VERSION "example frame map for dual-can-logger-esp32 - placeholder ids, replace with your own"

NS_ :

BS_:

BU_ NodeA NodeB Host

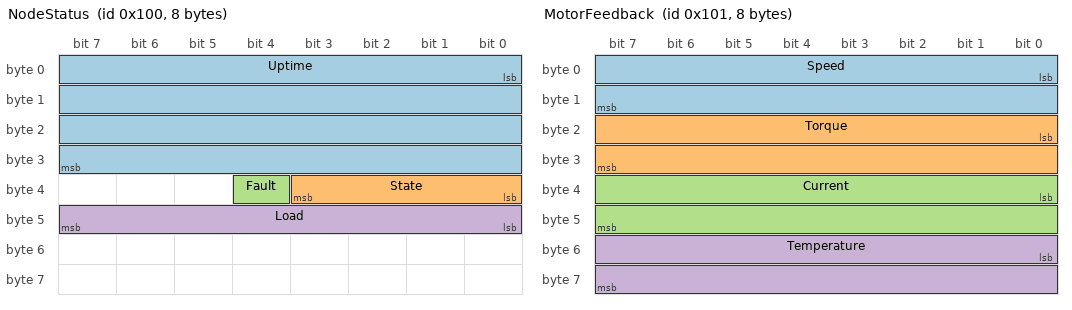
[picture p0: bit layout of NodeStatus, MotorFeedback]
BO_ 256 NodeStatus: 8 NodeA
 SG_ Uptime : 0|32@1+ (1,0) [0|4294967295] "s" Vector__XXX
 SG_ State : 32|4@1+ (1,0) [0|15] "" Vector__XXX
 SG_ Fault : 36|1@1+ (1,0) [0|1] "" Vector__XXX
 SG_ Load : 40|8@1+ (0.5,0) [0|127.5] "%" Vector__XXX

BO_ 257 MotorFeedback: 8 NodeA
 SG_ Speed : 0|16@1- (0.25,0) [-8192|8191.75] "rpm" Vector__XXX
 SG_ Torque : 16|16@1- (0.01,0) [-327.68|327.67] "Nm" Vector__XXX
 SG_ Current : 32|16@1+ (0.001,0) [0|65.535] "A" Vector__XXX
 SG_ Temperature : 48|16@1- (0.1,0) [-3276.8|3276.7] "degC" Vector__XXX

BO_ 258 SampleClock: 8 NodeA
 SG_ SampleTime : 0|32@1+ (1,0) [0|4294967295] "us" Vector__XXX
 SG_ Sequence : 32|16@1+ (1,0) [0|65535] "" Vector__XXX

BO_ 288 HostCommand: 8 Host
 SG_ Command M : 0|8@1+ (1,0) [0|255] "" NodeA
 SG_ Setpoint m16 : 8|32@1- (1e-06,0) [-2147.483648|2147.483647] "" NodeA
 SG_ WheelDia_mm m32 : 8|16@1+ (1,0) [300|3000] "mm" NodeA

BO_ 512 Diagnostics: 8 NodeA
 SG_ Page M : 0|8@1+ (1,0) [0|255] "" Vector__XXX
 SG_ SupplyVoltage m0 : 8|16@1+ (0.01,0) [0|655.35] "V" Vector__XXX
 SG_ BoardTemp m0 : 24|16@1- (0.1,0) [-3276.8|3276.7] "degC" Vector__XXX
 SG_ RunHours m1 : 8|32@1+ (1,0) [0|4294967295] "h" Vector__XXX
 SG_ ErrorCount m1 : 40|16@1+ (1,0) [0|65535] "" Vector__XXX

BO_ 2566868992 PressureExtended: 4 NodeB
 SG_ Pressure : 7|16@0+ (0.5,-100) [-100|32667.5] "kPa" Vector__XXX
 SG_ SensorOk : 16|1@1+ (1,0) [0|1] "" Vector__XXX

CM_ BO_ 288 "Sent BY the Host, i.e. by this logger - a command, not a reading.
Multiplexed: Command selects which payload the rest of the frame carries, so
Command and the payload signal have to go out in the SAME frame. Setting
WheelDia_mm alone would arrive as Command 0 and be ignored";
CM_ BO_ 512 "Multiplexed: Page selects which of the two pages the payload carries";
CM_ BO_ 2566868992 "A 29-bit identifier. In a DBC these carry bit 31 set, so the
number here is 0x18FF5000 | 0x80000000";
CM_ SG_ 258 SampleTime "Free-running microsecond clock inside the sending node";
CM_ SG_ 2566868992 Pressure "Big-endian (Motorola) layout, with a non-zero offset";

BA_DEF_ SG_ "Unwrap" INT 0 1;
BA_DEF_DEF_ "Unwrap" 0;
BA_ "Unwrap" SG_ 258 SampleTime 1;

VAL_ 256 State 0 "boot" 1 "ready" 2 "running" 3 "stopping" 5 "fault" ;
VAL_ 256 Fault 0 "ok" 1 "fault" ;
VAL_ 288 Command 1 "start" 2 "stop" 3 "calibrate" 16 "set_gain" 32 "wheel_diameter" ;
VAL_ 2566868992 SensorOk 0 "invalid" 1 "valid" ;
